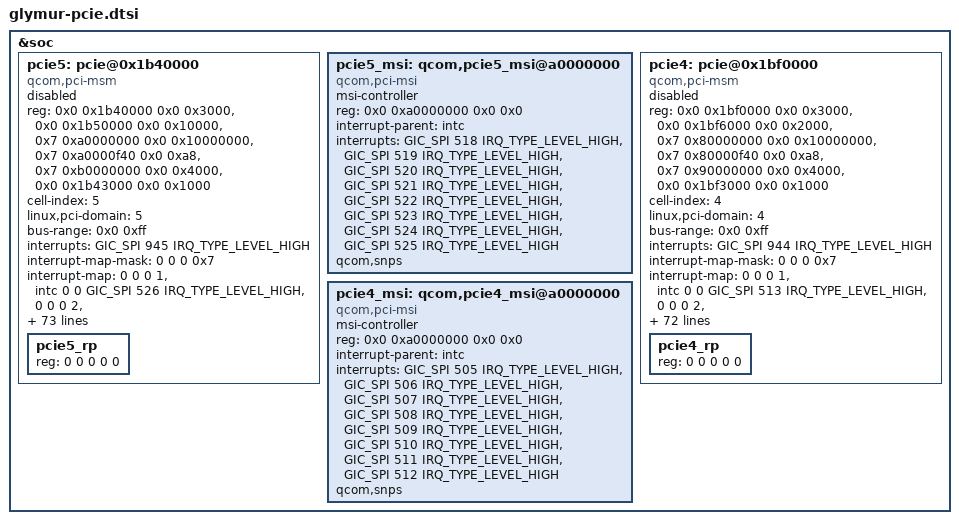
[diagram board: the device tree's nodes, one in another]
// SPDX-License-Identifier: BSD-3-Clause
/*
 * Copyright (c) Qualcomm Technologies, Inc. and/or its subsidiaries.
 */

#include <dt-bindings/gpio/gpio.h>
#include <dt-bindings/interconnect/qcom,glymur-rpmh.h>
#include <dt-bindings/clock/qcom,glymur-gcc.h>

&soc {
	pcie5: pcie@0x1b40000 {
		compatible = "qcom,pci-msm";

		reg = <0x0 0x1b40000 0x0 0x3000>,
		      <0x0 0x1b50000 0x0 0x10000>,
		      <0x7 0xa0000000 0x0 0x10000000>,
		      <0x7 0xa0000f40 0x0 0xa8>,
		      <0x7 0xb0000000 0x0 0x4000>,
		      <0x0 0x1b43000 0x0 0x1000>;
		reg-names = "parf", "phy", "dm_core", "elbi", "iatu", "mhi";

		cell-index = <5>;
		linux,pci-domain = <5>;
		bus-range = <0x0 0xff>;

		#address-cells = <3>;
		#size-cells = <2>;

		ranges = <0x01000000 0x0 0x7a200000 0x0 0x7a200000 0x0 0x100000>,
			 <0x02000000 0x0 0x7a300000 0x0 0x7a300000 0x0 0x3d00000>,
			 <0x43000000 0x7 0xb0004000 0x7 0xb0004000 0x0 0x2ffff000>;

		device_type = "pci";

		interrupts = <GIC_SPI 945 IRQ_TYPE_LEVEL_HIGH>;
		interrupt-names = "int_global_int";

		#interrupt-cells = <1>;
		interrupt-map-mask = <0 0 0 0x7>;

		interrupt-map = <0 0 0 1 &intc 0 0 GIC_SPI 526 IRQ_TYPE_LEVEL_HIGH>,
				<0 0 0 2 &intc 0 0 GIC_SPI 428 IRQ_TYPE_LEVEL_HIGH>,
				<0 0 0 3 &intc 0 0 GIC_SPI 429 IRQ_TYPE_LEVEL_HIGH>,
				<0 0 0 4 &intc 0 0 GIC_SPI 435 IRQ_TYPE_LEVEL_HIGH>;

		msi-parent = <&pcie5_msi>;

		perst-gpio = <&tlmm 152 GPIO_ACTIVE_HIGH>;
		wake-gpio = <&tlmm 154 GPIO_ACTIVE_HIGH>;

		pinctrl-names = "init", "default", "sleep";
		pinctrl-0 = <&pcie5_perst_init
				&pcie5_perst_default
				&pcie5_clkreq_default
				&pcie5_wake_default>;
		pinctrl-1 = <&pcie5_perst_default
				&pcie5_clkreq_default
				&pcie5_wake_default>;
		pinctrl-2 = <&pcie5_perst_default
				&pcie5_clkreq_sleep
				&pcie5_wake_default>;

		interconnect-names = "icc_path";
		interconnects = <&pcie_east_anoc MASTER_PCIE_5 &mc_virt SLAVE_EBI1>;

		power-domains = <&gcc GCC_PCIE_5_GDSC>, <&gcc GCC_PCIE_5_PHY_GDSC>;
		power-domain-names = "gdsc-core-vdd", "gdsc-phy-vdd";
		vreg-1p2-supply = <&L4H_E0>;
		vreg-0p9-supply = <&L2F_E0>;
		vreg-cx-supply = <&VDD_CX_LEVEL>;
		vreg-mx-supply = <&VDD_MXA_LEVEL>;

		qcom,vreg-1p2-voltage-level = <1200000 1200000 466680>;
		qcom,vreg-0p9-voltage-level = <936000 936000 777040>;
		qcom,vreg-cx-voltage-level = <RPMH_REGULATOR_LEVEL_MAX
						RPMH_REGULATOR_LEVEL_LOW_SVS 0>;
		qcom,vreg-mx-voltage-level = <RPMH_REGULATOR_LEVEL_MAX
						RPMH_REGULATOR_LEVEL_LOW_SVS 0>;

		clocks = <&gcc GCC_PCIE_5_PIPE_CLK>,
			<&rpmhcc RPMH_CXO_CLK>,
			<&gcc GCC_PCIE_5_AUX_CLK>,
			<&gcc GCC_PCIE_5_CFG_AHB_CLK>,
			<&gcc GCC_PCIE_5_MSTR_AXI_CLK>,
			<&gcc GCC_PCIE_5_SLV_AXI_CLK>,
			<&gcc GCC_PCIE_5_SLV_Q2A_AXI_CLK>,
			<&gcc GCC_PCIE_5_PHY_RCHNG_CLK>,
			<&gcc GCC_AGGRE_NOC_PCIE_5_EAST_SF_AXI_CLK>,
			<&gcc GCC_PCIE_5_PIPE_CLK_SRC>,
			<&gcc GCC_PCIE_5_PIPE_DIV2_CLK>,
			<&gcc GCC_CFG_NOC_PCIE_ANOC_SOUTH_AHB_CLK>,
			<&pcie_5_pipe_clk>,
			<&gcc GCC_PCIE_PHY_5_AUX_CLK>,
			<&gcc GCC_PCIE_PHY_5_AUX_CLK_SRC>,
			<&tcsrcc TCSR_PCIE_1_CLKREF_EN>;
		clock-names = "pcie_pipe_clk",
			"pcie_ref_clk_src",
			"pcie_aux_clk",
			"pcie_cfg_ahb_clk",
			"pcie_mstr_axi_clk",
			"pcie_slv_axi_clk",
			"pcie_slv_q2a_axi_clk",
			"pcie_rate_change_clk",
			"gcc_aggre_noc_pcie_5_east_sf_axi_clk",
			"pcie_pipe_clk_mux",
			"pcie_5_pipe_div2_clk",
			"pcie_cfg_noc_pcie_anoc_south_ahb_clk",
			"pcie_pipe_clk_ext_src",
			"gcc_pcie_phy_5_aux_clk",
			"gcc_pcie_phy_5_aux_clk_src",
			"pcie_clkref_en";

		qcom,pcie-clock-frequency = <0>, <0>, <19200000>, <0>, <0>, <0>, <0>,
				<100000000>, <0>, <0>, <0>, <0>, <0>, <0>, <0>, <0>;
		clock-suppressible = <0>, <0>, <0>, <0>, <0>, <0>, <0>,
				<0>, <0>, <0>, <0>, <0>, <0>, <0>, <0>, <0>;

		qcom,bw-scale = /* Gen1 */
				<RPMH_REGULATOR_LEVEL_LOW_SVS
				RPMH_REGULATOR_LEVEL_LOW_SVS
				19200000
				/* Gen2 */
				RPMH_REGULATOR_LEVEL_LOW_SVS
				RPMH_REGULATOR_LEVEL_LOW_SVS
				19200000
				/* Gen3 */
				RPMH_REGULATOR_LEVEL_LOW_SVS
				RPMH_REGULATOR_LEVEL_LOW_SVS
				100000000
				/* Gen4 */
				RPMH_REGULATOR_LEVEL_LOW_SVS
				RPMH_REGULATOR_LEVEL_LOW_SVS
				100000000
				/* Gen5 */
				RPMH_REGULATOR_LEVEL_NOM
				RPMH_REGULATOR_LEVEL_NOM
				100000000>;

		resets = <&gcc GCC_PCIE_5_BCR>,
				<&gcc GCC_PCIE_5_PHY_BCR>;
		reset-names ="pcie_5_core_reset",
				"pcie_5_phy_reset";

		dma-coherent;

		/* Glymur has SMMUv3 */
		iommu-map = <0x0 &pcie_smmu 0x50000 0x1>,
				<0x100 &pcie_smmu 0x50100 0x1>;

		qcom,no-l0s-supported;
		qcom,target-link-speed = <0x4>;
		qcom,target-link-width = <0x4>;
		qcom,no-client-based-bw-voting;
		qcom,boot-option = <0x2>;
		qcom,aux-clk-freq = <20>; /* 19.2 MHz */
		qcom,drv-l1ss-timeout-us = <5000>;
		qcom,l1-2-th-scale = <2>;
		qcom,l1-2-th-value = <150>;
		qcom,ep-latency = <10>;
		qcom,num-parf-testbus-sel = <0xb9>;

		qcom,pcie-phy-ver = <217>;
		qcom,phy-status-offset = <0x9010>;
		qcom,phy-status-bit = <7>;
		qcom,phy-power-down-offset = <0x9064>;

		qcom,phy-sequence = <0x9064 0x03 0x0
				0xd31c 0x1c 0x0
				0xd114 0xcf 0x0
				0xd118 0xa1 0x0
				0xd11c 0x7c 0x0
				0xd120 0x71 0x0
				0xd124 0x02 0x0
				0xd128 0x5e 0x0
				0xd12c 0x12 0x0
				0xd130 0x23 0x0
				0xd134 0xce 0x0
				0xd138 0xb3 0x0
				0xd13c 0x38 0x0
				0xd140 0x60 0x0
				0xd144 0x2c 0x0
				0xd148 0x5d 0x0
				0xd14c 0x2d 0x0
				0xd150 0x3b 0x0
				0xd154 0xaf 0x0
				0xd158 0xc6 0x0
				0xd15c 0xc3 0x0
				0xd160 0x70 0x0
				0xd164 0x8c 0x0
				0xd168 0x5e 0x0
				0xd16c 0x64 0x0
				0xd170 0x7a 0x0
				0xd2a8 0x6f 0x0
				0xd52c 0x02 0x0
				0xd530 0x0d 0x0
				0xd51c 0x20 0x0
				0xd53c 0x30 0x0
				0xd0f4 0xef 0x0
				0xd0f8 0x48 0x0
				0xd0fc 0x5c 0x0
				0xd100 0x51 0x0
				0xd104 0x2a 0x0
				0xd108 0x47 0x0
				0xd10c 0x08 0x0
				0xd110 0x1d 0x0
				0xd094 0x05 0x0
				0xd098 0x00 0x0
				0xd09c 0x41 0x0
				0xd0a0 0x00 0x0
				0xd070 0x00 0x0
				0xd074 0x00 0x0
				0xd078 0x80 0x0
				0xd07c 0x8d 0x0
				0xd50c 0x1c 0x0
				0xd510 0x1c 0x0
				0xd514 0x18 0x0
				0xd518 0x10 0x0
				0xd368 0x07 0x0
				0xd36c 0x07 0x0
				0xd370 0x0a 0x0
				0xd374 0x0a 0x0
				0xd378 0x0a 0x0
				0xd37c 0x03 0x0
				0xd380 0x04 0x0
				0xd384 0x01 0x0
				0xd388 0x03 0x0
				0xd38c 0x03 0x0
				0xd390 0x94 0x0
				0xd398 0x66 0x0
				0xd39c 0x57 0x0
				0xd3a0 0x07 0x0
				0xd3a4 0x00 0x0
				0xd3a8 0x22 0x0
				0xd3ac 0x00 0x0
				0xd3b0 0x33 0x0
				0xd3b4 0x32 0x0
				0xd3b8 0x03 0x0
				0xd3bc 0x00 0x0
				0xd3c0 0x00 0x0
				0xd3c4 0x02 0x0
				0xd600 0x14 0x0
				0xd604 0x14 0x0
				0xd608 0x14 0x0
				0xd60c 0x14 0x0
				0xd610 0x03 0x0
				0xd548 0x5a 0x0
				0xd258 0xff 0x0
				0xd260 0xff 0x0
				0xd268 0xff 0x0
				0xd270 0xff 0x0
				0xd278 0xff 0x0
				0xd280 0x10 0x0
				0xd284 0x16 0x0
				0xd288 0x0a 0x0
				0xd28c 0x07 0x0
				0xd290 0x08 0x0
				0xd550 0x11 0x0
				0xd56c 0x03 0x0
				0xd584 0x00 0x0
				0xd58c 0x5f 0x0
				0xd1b4 0x13 0x0
				0xd1b8 0x13 0x0
				0xd1bc 0x26 0x0
				0xd1c0 0x26 0x0
				0xd1c4 0x85 0x0
				0xd1c8 0x1e 0x0
				0xd1cc 0xcc 0x0
				0xd1d0 0x3d 0x0
				0xd1d4 0xcc 0x0
				0xd1d8 0x3d 0x0
				0xd2c8 0x83 0x0
				0xd2cc 0x44 0x0
				0xd2d0 0x02 0x0
				0xd454 0x0a 0x0
				0xd458 0xaa 0x0
				0xd45c 0x0a 0x0
				0xd490 0xdd 0x0
				0xd494 0xdb 0x0
				0xd498 0x04 0x0
				0xd5ac 0x15 0x0
				0xd3c8 0x7f 0x0
				0xd3cc 0x01 0x0
				0xd220 0x2b 0x0
				0xd224 0x00 0x0
				0xd228 0x20 0x0
				0xd22c 0x00 0x0
				0xd230 0x35 0x0
				0xd234 0x00 0x0
				0xd238 0x35 0x0
				0xd240 0x20 0x0
				0xd1e8 0x11 0x0
				0xd1ec 0x11 0x0
				0xd1f0 0x01 0x0
				0xd33c 0xff 0x0
				0xd340 0xff 0x0
				0xd344 0xff 0x0
				0xd348 0xff 0x0
				0xd34c 0xff 0x0
				0xd1dc 0x34 0x0
				0xd1e0 0x43 0x0
				0xd1e4 0x03 0x0
				0xd3d0 0x07 0x0
				0xd254 0x03 0x0
				0xd1fc 0x03 0x0
				0xd204 0x04 0x0
				0xd3dc 0xd0 0x0
				0xd404 0xcc 0x0
				0xd408 0x8a 0x0
				0xd40c 0x09 0x0
				0xd3d4 0x1f 0x0
				0xd0bc 0x16 0x0
				0xd3e4 0x08 0x0
				0xd3f4 0x17 0x0
				0xd0b0 0x08 0x0
				0xd0b8 0x10 0x0
				0xd47c 0x67 0x0
				0xd488 0x00 0x0
				0xd4a4 0x04 0x0
				0xd04c 0x40 0x0
				0xd5b8 0x11 0x0
				0xd5bc 0x11 0x0
				0xd5c4 0x1e 0x0
				0xd5c8 0x1e 0x0
				0xd5cc 0x1e 0x0
				0xd5d0 0x1e 0x0
				0xd5d4 0x1e 0x0
				0xd320 0x2f 0x0
				0xd324 0x84 0x0
				0xd334 0x66 0x0
				0xd7ec 0x6e 0x0
				0xd310 0xff 0x0
				0xd4bc 0x56 0x0
				0xd360 0x80 0x0
				0xd3e0 0x10 0x0
				0xd5fc 0x20 0x0
				0x82f4 0x0f 0x0
				0x81cc 0xab 0x0
				0x81d0 0x01 0x0
				0x81dc 0x06 0x0
				0x81e0 0x16 0x0
				0x81e4 0x36 0x0
				0x81e8 0x04 0x0
				0x81ec 0x0a 0x0
				0x81f0 0x1a 0x0
				0x81f4 0x68 0x0
				0x81fc 0xab 0x0
				0x8200 0xaa 0x0
				0x8204 0x02 0x0
				0x8220 0xa4 0x0
				0x8224 0x18 0x0
				0x8000 0x00 0x0
				0x8004 0x03 0x0
				0x8010 0x06 0x0
				0x8014 0x16 0x0
				0x8018 0x36 0x0
				0x801c 0x04 0x0
				0x8020 0x04 0x0
				0x8024 0x0d 0x0
				0x8028 0x68 0x0
				0x8030 0xab 0x0
				0x8034 0xaa 0x0
				0x8038 0x02 0x0
				0x8050 0x52 0x0
				0x8054 0x0c 0x0
				0x803c 0x3c 0x0
				0x821c 0x01 0x0
				0x81a0 0x3c 0x0
				0x8230 0x01 0x0
				0x8060 0xe0 0x0
				0x8064 0x01 0x0
				0x8070 0x06 0x0
				0x8074 0x16 0x0
				0x8078 0x36 0x0
				0x807c 0x0a 0x0
				0x8080 0x40 0x0
				0x8084 0x03 0x0
				0x8088 0x41 0x0
				0x8090 0xab 0x0
				0x8094 0xaa 0x0
				0x8098 0x01 0x0
				0x8058 0xd4 0x0
				0x805c 0x03 0x0
				0x809c 0x16 0x0
				0x8228 0x00 0x0
				0x80bc 0x0a 0x0
				0x813c 0x40 0x0
				0x80c0 0x01 0x0
				0x80cc 0x62 0x0
				0x80d0 0x02 0x0
				0x80d8 0xc0 0x0
				0x80dc 0x1f 0x0
				0x80e0 0x90 0x0
				0x80e4 0x82 0x0
				0x80f4 0x0f 0x0
				0x8110 0x08 0x0
				0x8120 0x46 0x0
				0x8124 0x04 0x0
				0x8140 0x24 0x0
				0x8164 0x34 0x0
				0x8170 0xe0 0x0
				0x8174 0x86 0x0
				0x8188 0x88 0x0
				0x818c 0x14 0x0
				0x819c 0x0f 0x0
				0x822c 0x10 0x0
				0x800c 0x14 0x0
				0x806c 0x32 0x0
				0x82f0 0x05 0x0
				0x82b8 0x40 0x0
				0x82d8 0x40 0x0
				0x82dc 0x07 0x0
				0x82e0 0x60 0x0
				0x8300 0x20 0x0
				0x8304 0x36 0x0
				0x8308 0x20 0x0
				0x82fc 0xaf 0x0
				0x80fc 0x1b 0x0
				0x906c 0x3d 0x0
				0x9078 0xe4 0x0
				0x907c 0x1f 0x0
				0x9080 0x0d 0x0
				0x90a0 0xe4 0x0
				0x90a4 0x30 0x0
				0x90ac 0x05 0x0
				0x90b0 0x08 0x0
				0x90b4 0x20 0x0
				0x90b8 0x20 0x0
				0x90c0 0x40 0x0
				0x90c8 0xc1 0x0
				0x90ec 0x66 0x0
				0x9194 0x00 0x0
				0x91c0 0x00 0x0
				0x91dc 0x00 0x0
				0x91e0 0x04 0x0
				0x91e4 0x1f 0x0
				0x91f4 0x35 0x0
				0x91f8 0x3e 0x0
				0x9380 0x06 0x0
				0x9384 0x1c 0x0
				0x938c 0x07 0x0
				0x9394 0x00 0x0
				0x93a4 0x00 0x0
				0x93b4 0x90 0x0
				0x93bc 0x0d 0x0
				0x93c8 0x00 0x0
				0x93d8 0x90 0x0
				0x93e0 0x0d 0x0
				0x93ec 0x00 0x0
				0x93fc 0x90 0x0
				0x9404 0x0d 0x0
				0xe8e0 0x00 0x0
				0xe8f8 0x00 0x0
				0x9060 0x00 0x0
				0x905c 0x03 0x0>;

		status = "disabled";

		pcie5_rp: pcie5_rp {
				reg = <0 0 0 0 0>;
		};
	};

	pcie5_msi: qcom,pcie5_msi@a0000000 {
		compatible = "qcom,pci-msi";
		msi-controller;
		reg = <0x0 0xa0000000 0x0 0x0>;
		interrupt-parent = <&intc>;
		interrupts =
			<GIC_SPI 518 IRQ_TYPE_LEVEL_HIGH>,
			<GIC_SPI 519 IRQ_TYPE_LEVEL_HIGH>,
			<GIC_SPI 520 IRQ_TYPE_LEVEL_HIGH>,
			<GIC_SPI 521 IRQ_TYPE_LEVEL_HIGH>,
			<GIC_SPI 522 IRQ_TYPE_LEVEL_HIGH>,
			<GIC_SPI 523 IRQ_TYPE_LEVEL_HIGH>,
			<GIC_SPI 524 IRQ_TYPE_LEVEL_HIGH>,
			<GIC_SPI 525 IRQ_TYPE_LEVEL_HIGH>;
		qcom,snps;
	};

	pcie4: pcie@0x1bf0000 {
		compatible = "qcom,pci-msm";

		reg = <0x0 0x1bf0000 0x0 0x3000>,
		      <0x0 0x1bf6000 0x0 0x2000>,
		      <0x7 0x80000000 0x0 0x10000000>,
		      <0x7 0x80000f40 0x0 0xa8>,
		      <0x7 0x90000000 0x0 0x4000>,
		      <0x0 0x1bf3000 0x0 0x1000>;
		reg-names = "parf", "phy", "dm_core", "elbi", "iatu", "mhi";
		#address-cells = <3>;
		#size-cells = <2>;
		ranges = <0x01000000 0x0 0x78200000 0x0 0x78200000 0x0 0x100000>,
			<0x02000000 0x0 0x78300000 0x0 0x78300000 0x0 0x1d00000>,
			<0x43000000 0x7 0x90004000 0x7 0x90004000 0x0 0xfffc000>;

		cell-index = <4>;
		linux,pci-domain = <4>;
		bus-range = <0x0 0xff>;

		device_type = "pci";
		interrupts = <GIC_SPI 944 IRQ_TYPE_LEVEL_HIGH>;
		interrupt-names = "int_global_int";

		#interrupt-cells = <1>;
		interrupt-map-mask = <0 0 0 0x7>;
		interrupt-map = <0 0 0 1 &intc 0 0 GIC_SPI 513 IRQ_TYPE_LEVEL_HIGH>,
				<0 0 0 2 &intc 0 0 GIC_SPI 514 IRQ_TYPE_LEVEL_HIGH>,
				<0 0 0 3 &intc 0 0 GIC_SPI 515 IRQ_TYPE_LEVEL_HIGH>,
				<0 0 0 4 &intc 0 0 GIC_SPI 516 IRQ_TYPE_LEVEL_HIGH>;

		msi-parent = <&pcie4_msi>;

		perst-gpio = <&tlmm 146 GPIO_ACTIVE_HIGH>;
		wake-gpio = <&tlmm 148 GPIO_ACTIVE_HIGH>;

		pinctrl-names = "default", "sleep";
		pinctrl-0 = <&pcie4_perst_default
				&pcie4_clkreq_default
				&pcie4_wake_default>;
		pinctrl-1 = <&pcie4_perst_default
				&pcie4_clkreq_sleep
				&pcie4_wake_default>;

		interconnect-names = "icc_path";
		interconnects = <&pcie_west_anoc MASTER_PCIE_4 &mc_virt SLAVE_EBI1>;

		power-domains = <&gcc GCC_PCIE_4_GDSC>, <&gcc GCC_PCIE_4_PHY_GDSC>;
		power-domain-names = "gdsc-core-vdd", "gdsc-phy-vdd";
		vreg-1p2-supply = <&L4F_E1>;
		vreg-0p9-supply = <&L1C_E1>;
		vreg-qref-supply = <&L1F_E1>;
		vreg-qref1-supply = <&L2F_E1>;
		vreg-cx-supply = <&VDD_CX_LEVEL>;
		vreg-mx-supply = <&VDD_MXA_LEVEL>;
		qcom,vreg-1p2-voltage-level = <1200000 1200000 189900>;
		qcom,vreg-0p9-voltage-level = <912000 912000 219070>;
		qcom,vreg-qref-voltage-level = <940000 940000 1340>;
		qcom,vreg-qref1-voltage-level = <880000 880000 1340>;
		qcom,vreg-cx-voltage-level = <RPMH_REGULATOR_LEVEL_MAX
						RPMH_REGULATOR_LEVEL_LOW_SVS 0>;
		qcom,vreg-mx-voltage-level = <RPMH_REGULATOR_LEVEL_MAX
						RPMH_REGULATOR_LEVEL_LOW_SVS 0>;

		clocks = <&gcc GCC_PCIE_4_PIPE_CLK>,
			<&rpmhcc RPMH_CXO_CLK>,
			<&gcc GCC_PCIE_4_AUX_CLK>,
			<&gcc GCC_PCIE_4_CFG_AHB_CLK>,
			<&gcc GCC_PCIE_4_MSTR_AXI_CLK>,
			<&gcc GCC_PCIE_4_SLV_AXI_CLK>,
			<&gcc GCC_PCIE_4_SLV_Q2A_AXI_CLK>,
			<&gcc GCC_PCIE_4_PHY_RCHNG_CLK>,
			<&gcc GCC_AGGRE_NOC_PCIE_4_WEST_SF_AXI_CLK>,
			<&gcc GCC_PCIE_4_PIPE_CLK_SRC>,
			<&gcc GCC_PCIE_4_PIPE_DIV2_CLK>,
			<&gcc GCC_CFG_NOC_PCIE_ANOC_AHB_CLK>,
			<&pcie_4_pipe_clk>,
			<&gcc GCC_PCIE_PHY_4_AUX_CLK>,
			<&tcsrcc TCSR_PCIE_2_CLKREF_EN>;

		clock-names = "pcie_pipe_clk",
			"pcie_ref_clk_src",
			"pcie_aux_clk",
			"pcie_cfg_ahb_clk",
			"pcie_mstr_axi_clk",
			"pcie_slv_axi_clk",
			"pcie_slv_q2a_axi_clk",
			"pcie_rate_change_clk",
			"gcc_aggre_noc_pcie_4_west_sf_axi_clk",
			"pcie_pipe_clk_mux",
			"pcie_4_pipe_div2_clk",
			"pcie_cfg_noc_pcie_anoc_ahb_clk",
			"pcie_pipe_clk_ext_src",
			"pcie_phy_aux_clk",
			"pcie_clkref_en";

		qcom,pcie-clock-frequency = <0>, <0>, <19200000>, <0>, <0>, <0>, <0>,
				<100000000>, <0>, <0>, <0>, <0>, <0>, <0>, <0>;
		clock-suppressible = <0>, <0>, <0>, <0>, <0>, <0>, <0>,
				<0>, <0>, <0>, <0>, <0>, <0>, <0>, <0>;

		qcom,bw-scale = /* Gen1 */
				<RPMH_REGULATOR_LEVEL_LOW_SVS
				RPMH_REGULATOR_LEVEL_LOW_SVS
				19200000
				/* Gen2 */
				RPMH_REGULATOR_LEVEL_LOW_SVS
				RPMH_REGULATOR_LEVEL_LOW_SVS
				19200000
				/* Gen3 */
				RPMH_REGULATOR_LEVEL_LOW_SVS
				RPMH_REGULATOR_LEVEL_LOW_SVS
				100000000
				/* Gen4 */
				RPMH_REGULATOR_LEVEL_LOW_SVS
				RPMH_REGULATOR_LEVEL_LOW_SVS
				100000000>;

		resets = <&gcc GCC_PCIE_4_BCR>,
				<&gcc GCC_PCIE_4_PHY_BCR>;
		reset-names = "pcie_4_core_reset",
				 "pcie_4_phy_reset";

		dma-coherent;

		/* Glymur has SMMUv3 */
		iommu-map = <0x0 &pcie_smmu 0x40000 0x1>,
				<0x100 &pcie_smmu 0x40100 0x1>;

		qcom,target-link-speed = <0x4>;
		qcom,boot-option = <0x1>;
		qcom,aux-clk-freq = <20>; /* 19.2 MHz */
		qcom,drv-l1ss-timeout-us = <5000>;
		qcom,l1-2-th-scale = <2>;
		qcom,l1-2-th-value = <150>;
		qcom,ep-latency = <10>;
		qcom,num-parf-testbus-sel = <0xb9>;

		qcom,pcie-phy-ver = <1400>;
		qcom,phy-status-offset = <0x414>;
		qcom,phy-status-bit = <7>;
		qcom,phy-power-down-offset = <0x440>;

		qcom,phy-sequence = <0x1440 0x03 0x0
				0x0030 0x1d 0x0
				0x0034 0x17 0x0
				0x007c 0x00 0x0
				0x0080 0x40 0x0
				0x0084 0x00 0x0
				0x00b4 0x04 0x0
				0x00e0 0x05 0x0
				0x00e4 0x00 0x0
				0x00f4 0x07 0x0
				0x00f8 0x1f 0x0
				0x0058 0x90 0x0
				0x0118 0x02 0x0
				0x011c 0x0d 0x0
				0x0148 0x53 0x0
				0x014c 0x54 0x0
				0x02dc 0x0b 0x0
				0x02ec 0x04 0x0
				0x02f0 0x05 0x0
				0x02f4 0x15 0x0
				0x0370 0x00 0x0
				0x0378 0x89 0x0
				0x03b4 0x2d 0x0
				0x0128 0x20 0x0
				0x03d8 0x1c 0x0
				0x03dc 0x2f 0x0
				0x03e0 0x84 0x0
				0x02b8 0x01 0x0
				0x02bc 0x05 0x0
				0x02c4 0x00 0x0
				0x02c8 0x00 0x0
				0x02b4 0x00 0x0
				0x0258 0x40 0x0
				0x025c 0x42 0x0
				0x0284 0x18 0x0
				0x0298 0x12 0x0
				0x02ac 0x18 0x0
				0x0418 0xc2 0x0
				0x041c 0xc2 0x0
				0x0420 0x18 0x0
				0x0428 0x0f 0x0
				0x0434 0x62 0x0
				0x0460 0xe4 0x0
				0x0464 0x63 0x0
				0x0468 0xd8 0x0
				0x046c 0x99 0x0
				0x0470 0x67 0x0
				0x0484 0xa4 0x0
				0x0488 0xa4 0x0
				0x048c 0x28 0x0
				0x0490 0x9f 0x0
				0x0494 0x48 0x0
				0x0498 0x24 0x0
				0x051c 0x01 0x0
				0x0520 0x00 0x0
				0x0578 0x00 0x0
				0x057c 0x08 0x0
				0x0580 0x88 0x0
				0x031c 0xff 0x0
				0x0320 0xff 0x0
				0x0308 0x30 0x0
				0x030c 0x03 0x0
				0x0398 0x1f 0x0
				0x039c 0x1f 0x0
				0x03a0 0x0d 0x0
				0x0830 0x1d 0x0
				0x0834 0x17 0x0
				0x087c 0x00 0x0
				0x0880 0x40 0x0
				0x0884 0x00 0x0
				0x08b4 0x04 0x0
				0x08e0 0x05 0x0
				0x08e4 0x00 0x0
				0x08f4 0x07 0x0
				0x08f8 0x1f 0x0
				0x0858 0x90 0x0
				0x0918 0x02 0x0
				0x091c 0x0d 0x0
				0x0948 0x53 0x0
				0x094c 0x54 0x0
				0x0adc 0x0b 0x0
				0x0aec 0x04 0x0
				0x0af0 0x05 0x0
				0x0af4 0x15 0x0
				0x0b70 0x00 0x0
				0x0b78 0x89 0x0
				0x0bb4 0x2d 0x0
				0x0928 0x20 0x0
				0x0bd8 0x1c 0x0
				0x0bdc 0x2f 0x0
				0x0be0 0x84 0x0
				0x0ab8 0x01 0x0
				0x0abc 0x05 0x0
				0x0ac4 0x00 0x0
				0x0ac8 0x00 0x0
				0x0ab4 0x00 0x0
				0x0a58 0x40 0x0
				0x0a5c 0x42 0x0
				0x0a84 0x18 0x0
				0x0a98 0x12 0x0
				0x0aac 0x18 0x0
				0x0c18 0xc2 0x0
				0x0c1c 0xc2 0x0
				0x0c20 0x18 0x0
				0x0c28 0x0f 0x0
				0x0c34 0x62 0x0
				0x0c60 0xe4 0x0
				0x0c64 0x63 0x0
				0x0c68 0xd8 0x0
				0x0c6c 0x99 0x0
				0x0c70 0x67 0x0
				0x0c84 0xa4 0x0
				0x0c88 0xa4 0x0
				0x0c8c 0x28 0x0
				0x0c90 0x9f 0x0
				0x0c94 0x48 0x0
				0x0c98 0x24 0x0
				0x0d1c 0x01 0x0
				0x0d20 0x00 0x0
				0x0d78 0x00 0x0
				0x0d7c 0x08 0x0
				0x0d80 0x88 0x0
				0x0b1c 0xff 0x0
				0x0b20 0xff 0x0
				0x0b08 0x30 0x0
				0x0b0c 0x03 0x0
				0x0b98 0x1f 0x0
				0x0b9c 0x1f 0x0
				0x0ba0 0x0d 0x0
				0x1000 0x93 0x0
				0x1004 0x01 0x0
				0x1010 0x06 0x0
				0x1014 0x16 0x0
				0x1018 0x36 0x0
				0x101c 0x04 0x0
				0x1020 0x0a 0x0
				0x1024 0x1a 0x0
				0x1028 0x34 0x0
				0x1030 0x55 0x0
				0x1034 0x55 0x0
				0x1038 0x01 0x0
				0x103c 0x01 0x0
				0x1040 0x3f 0x0
				0x1060 0xf8 0x0
				0x1064 0x01 0x0
				0x1070 0x06 0x0
				0x1074 0x16 0x0
				0x1078 0x36 0x0
				0x107c 0x0a 0x0
				0x1080 0x04 0x0
				0x1084 0x0d 0x0
				0x1088 0x41 0x0
				0x1090 0xab 0x0
				0x1094 0xaa 0x0
				0x1098 0x01 0x0
				0x109c 0x00 0x0
				0x10bc 0x0a 0x0
				0x10c0 0x01 0x0
				0x10cc 0x62 0x0
				0x10d0 0x02 0x0
				0x10dc 0x14 0x0
				0x10e0 0x90 0x0
				0x10e4 0x82 0x0
				0x10f4 0x0f 0x0
				0x1110 0x08 0x0
				0x1120 0x46 0x0
				0x1124 0x04 0x0
				0x1140 0x14 0x0
				0x1164 0x34 0x0
				0x1170 0xa0 0x0
				0x1174 0x16 0x0
				0x1184 0x88 0x0
				0x1188 0x04 0x0
				0x1198 0x0f 0x0
				0x12b4 0x02 0x0
				0x1570 0x17 0x0
				0x1578 0x2e 0x0
				0x1590 0xcc 0x0
				0x15b8 0x40 0x0
				0x15dc 0x08 0x0
				0x15e0 0x02 0x0
				0x1818 0xc0 0x0
				0x15f8 0x00 0x0
				0x15fc 0x22 0x0
				0x180c 0x1d 0x0
				0x181c 0xc1 0x0
				0x1890 0x00 0x0
				0x18a0 0x16 0x0
				0x18f0 0x27 0x0
				0x18f4 0x27 0x0
				0x1908 0x02 0x0
				0x195c 0x2e 0x0
				0x197c 0x03 0x0
				0x1984 0x28 0x0
				0x198c 0x00 0x0
				0x19ac 0x02 0x0
				0x19c0 0x02 0x0
				0x1b38 0x00 0x0
				0x1d38 0x00 0x0
				0x1d24 0x00 0x0
				0x1d28 0x00 0x0
				0x1400 0x00 0x0
				0x1444 0x03 0x0>;

		status = "disabled";

		pcie4_rp: pcie4_rp {
			reg = <0 0 0 0 0>;
		};
	};

	pcie4_msi: qcom,pcie4_msi@a0000000 {
		compatible = "qcom,pci-msi";
		msi-controller;
		reg = <0x0 0xa0000000 0x0 0x0>;
		interrupt-parent = <&intc>;
		interrupts = <GIC_SPI 505 IRQ_TYPE_LEVEL_HIGH>,
			<GIC_SPI 506 IRQ_TYPE_LEVEL_HIGH>,
			<GIC_SPI 507 IRQ_TYPE_LEVEL_HIGH>,
			<GIC_SPI 508 IRQ_TYPE_LEVEL_HIGH>,
			<GIC_SPI 509 IRQ_TYPE_LEVEL_HIGH>,
			<GIC_SPI 510 IRQ_TYPE_LEVEL_HIGH>,
			<GIC_SPI 511 IRQ_TYPE_LEVEL_HIGH>,
			<GIC_SPI 512 IRQ_TYPE_LEVEL_HIGH>;
		qcom,snps;
	};
};
